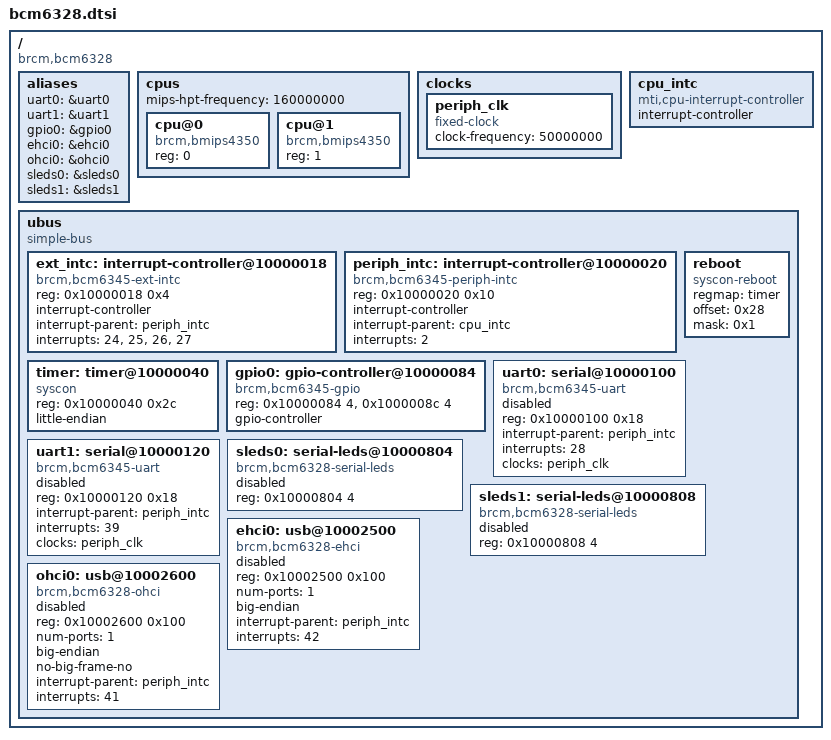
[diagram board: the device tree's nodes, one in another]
/ {
	#address-cells = <1>;
	#size-cells = <1>;
	compatible = "brcm,bcm6328";

	aliases {
		uart0 = &uart0;
		uart1 = &uart1;
		gpio0 = &gpio0;
		ehci0 = &ehci0;
		ohci0 = &ohci0;
		sleds0 = &sleds0;
		sleds1 = &sleds1;
	};

	cpus {
		#address-cells = <1>;
		#size-cells = <0>;

		mips-hpt-frequency = <160000000>;

		cpu@0 {
			compatible = "brcm,bmips4350";
			device_type = "cpu";
			reg = <0>;
		};

		cpu@1 {
			compatible = "brcm,bmips4350";
			device_type = "cpu";
			reg = <1>;
		};
	};

	clocks {
		periph_clk: periph_clk {
			compatible = "fixed-clock";
			#clock-cells = <0>;
			clock-frequency = <50000000>;
		};
	};

	cpu_intc: cpu_intc {
		#address-cells = <0>;
		compatible = "mti,cpu-interrupt-controller";

		interrupt-controller;
		#interrupt-cells = <1>;
	};

	ubus {
		#address-cells = <1>;
		#size-cells = <1>;

		compatible = "simple-bus";
		ranges;

		ext_intc: interrupt-controller@10000018 {
			compatible = "brcm,bcm6345-ext-intc";
			reg = <0x10000018 0x4>;

			interrupt-controller;
			#interrupt-cells = <2>;

			interrupt-parent = <&periph_intc>;
			interrupts = <24>, <25>, <26>, <27>;
		};

		periph_intc: interrupt-controller@10000020 {
			compatible = "brcm,bcm6345-periph-intc";
			reg = <0x10000020 0x10>;

			interrupt-controller;
			#interrupt-cells = <1>;

			interrupt-parent = <&cpu_intc>;
			interrupts = <2>;
		};

		timer: timer@10000040 {
			compatible = "syscon";
			reg = <0x10000040 0x2c>;
			little-endian;
		};

		reboot {
			compatible = "syscon-reboot";
			regmap = <&timer>;
			offset = <0x28>;
			mask = <0x1>;
		};

		gpio0: gpio-controller@10000084 {
			compatible = "brcm,bcm6345-gpio";
			reg = <0x10000084 4>, <0x1000008c 4>;

			gpio-controller;
			#gpio-cells = <2>;
		};

		uart0: serial@10000100 {
			compatible = "brcm,bcm6345-uart";
			reg = <0x10000100 0x18>;
			interrupt-parent = <&periph_intc>;
			interrupts = <28>;
			clocks = <&periph_clk>;
			status = "disabled";
		};

		uart1: serial@10000120 {
			compatible = "brcm,bcm6345-uart";
			reg = <0x10000120 0x18>;
			interrupt-parent = <&periph_intc>;
			interrupts = <39>;
			clocks = <&periph_clk>;
			status = "disabled";
		};

		sleds0: serial-leds@10000804 {
			compatible = "brcm,bcm6328-serial-leds";
			reg = <0x10000804 4>;
			reg-names = "dat";

			status = "disabled";
		};

		sleds1: serial-leds@10000808 {
			compatible = "brcm,bcm6328-serial-leds";
			reg = <0x10000808 4>;
			reg-names = "dat";

			status = "disabled";
		};

		ehci0: usb@10002500 {
			compatible = "brcm,bcm6328-ehci", "generic-ehci";
			reg = <0x10002500 0x100>;
			num-ports = <1>;
			big-endian;
			interrupt-parent = <&periph_intc>;
			interrupts = <42>;
			status = "disabled";
		};

		ohci0: usb@10002600 {
			compatible = "brcm,bcm6328-ohci", "generic-ohci";
			reg = <0x10002600 0x100>;
			num-ports = <1>;
			big-endian;
			no-big-frame-no;
			interrupt-parent = <&periph_intc>;
			interrupts = <41>;
			status = "disabled";
		};
	};
};
